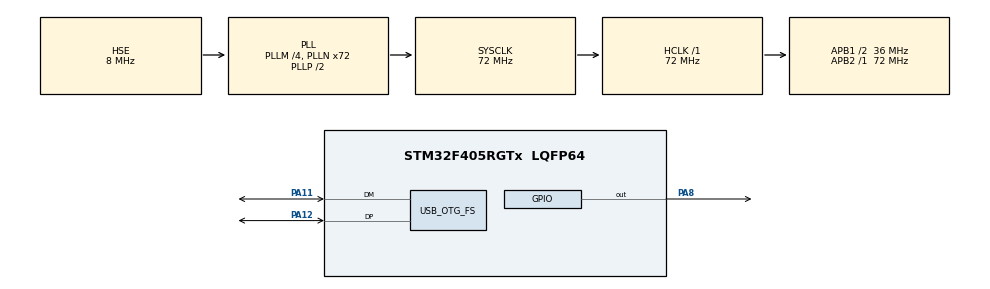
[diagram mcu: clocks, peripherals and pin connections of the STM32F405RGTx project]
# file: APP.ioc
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Mcu.Family=STM32F4
Mcu.Name=STM32F405RGTx
Mcu.Package=LQFP64
NVIC.OTG_FS_IRQn=true\:0\:0\:false\:false\:true\:false\:true\:true
NVIC.PriorityGroup=NVIC_PRIORITYGROUP_4
PA11.Mode=Device_Only
PA11.Signal=USB_OTG_FS_DM
PA12.Mode=Device_Only
PA12.Signal=USB_OTG_FS_DP
PA13.Mode=Serial_Wire
PA13.Signal=SYS_JTMS-SWDIO
PA14.Mode=Serial_Wire
PA14.Signal=SYS_JTCK-SWCLK
PA8.Signal=GPIO_Output
PH0-OSC_IN.Mode=HSE-External-Oscillator
PH0-OSC_IN.Signal=RCC_OSC_IN
PH1-OSC_OUT.Mode=HSE-External-Oscillator
PH1-OSC_OUT.Signal=RCC_OSC_OUT
ProjectManager.HeapSize=0x200
ProjectManager.StackSize=0x400
ProjectManager.TargetToolchain=MDK-ARM V5.32
RCC.48MHZClocksFreq_Value=48000000
RCC.AHBFreq_Value=72000000
RCC.APB1CLKDivider=RCC_HCLK_DIV2
RCC.APB1Freq_Value=36000000
RCC.APB1TimFreq_Value=72000000
RCC.APB2Freq_Value=72000000
RCC.APB2TimFreq_Value=72000000
RCC.CortexFreq_Value=72000000
RCC.HCLKFreq_Value=72000000
RCC.HSE_VALUE=8000000
RCC.HSI_VALUE=16000000
RCC.LSE_VALUE=32768
RCC.PLLM=4
RCC.PLLN=72
RCC.PLLQ=3
RCC.SYSCLKFreq_VALUE=72000000
RCC.SYSCLKSource=RCC_SYSCLKSOURCE_PLLCLK
RCC.VCOOutputFreq_Value=144000000
USB_DEVICE.CLASS_NAME_FS=CDC
USB_DEVICE.VirtualMode-CDC_FS=Cdc
USB_DEVICE.VirtualModeFS=Cdc_FS
USB_OTG_FS.VirtualMode=Device_Only
VP_USB_DEVICE_VS_USB_DEVICE_CDC_FS.Mode=CDC_FS
board=custom

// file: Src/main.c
/* USER CODE BEGIN Header */
/**
  ******************************************************************************
  * @file           : main.c
  * @brief          : Main program body
  ******************************************************************************
  * @attention
  *
  * Copyright (c) 2024 STMicroelectronics.
  * All rights reserved.
  *
  * This software is licensed under terms that can be found in the LICENSE file
  * in the root directory of this software component.
  * If no LICENSE file comes with this software, it is provided AS-IS.
  *
  ******************************************************************************
  */
/* USER CODE END Header */
#include "main.h"
#include "usb_device.h"
#include "gpio.h"

/* USER CODE BEGIN Includes */
#include "oled.h"
#include "usbd_cdc_if.h"
/* USER CODE END Includes */

/* USER CODE BEGIN PTD */

/* Flash 总大小和基地址 */
#define FLASH_BASE_ADDR       0x08000000    // Flash 起始地址
#define FLASH_TOTAL_SIZE      0x00100000    // 1MB 总大小

/* 每个部分的大小 */
#define FLASH_SIZE_APP0       0x00040000    // app0 大小：256KB (1MB / 4)
#define FLASH_SIZE_APP_BUF    0x00040000    // app_buf 大小：256KB
#define FLASH_SIZE_USER_VAR   0x00020000    // 用户变量大小：128KB (1MB / 8)
#define FLASH_SIZE_BOOTLOADER 0x00020000    // bootloader 大小：128KB
#define FLASH_SIZE_APP_INIT   0x00040000    // app_init 大小：256KB

/* 每个部分的起始地址 */
#define FLASH_ADDR_APP0       0x08000000    // app0 起始地址
#define FLASH_ADDR_APP_BUF    0x08040000    // app_buf 起始地址 (app0 起始地址 + 256KB)
#define FLASH_ADDR_USER_VAR   0x08080000    // 用户变量起始地址 (app_buf 起始地址 + 256KB)
#define FLASH_ADDR_BOOTLOADER 0x080A0000    // bootloader 起始地址 (用户变量起始地址 + 128KB)
#define FLASH_ADDR_APP_INIT   0x080C0000    // app_init 起始地址 (bootloader 起始地址 + 128KB)

#define ApplicationAddress     0x08004000
typedef  void (*pFunction)(void);
pFunction Jump_To_Application;
uint32_t JumpAddress;
extern USBD_HandleTypeDef hUsbDeviceFS;
/* USER CODE END PTD */

void SystemClock_Config(void);
/* USER CODE BEGIN PFP */

uint8_t jumpflag = 0;

void USB_DeInit(void)
{
  if (USBD_Stop(&hUsbDeviceFS) != USBD_OK)
  {
    Error_Handler();
  }
  if (USBD_DeInit(&hUsbDeviceFS) != USBD_OK)
  {
    Error_Handler();
  }
  HAL_Delay(100);
}

void USB_Init(void)
{
  GPIO_InitTypeDef GPIO_InitStruct = {0};

  /* GPIO Ports Clock Enable */
  __HAL_RCC_GPIOA_CLK_ENABLE();

  /*Configure GPIO pin Output Level */
  HAL_GPIO_WritePin(GPIOA, GPIO_PIN_11|GPIO_PIN_12, GPIO_PIN_RESET);

  /*Configure GPIO pin : PA8 */
  GPIO_InitStruct.Pin = GPIO_PIN_11|GPIO_PIN_12;
  GPIO_InitStruct.Mode = GPIO_MODE_OUTPUT_OD;
  GPIO_InitStruct.Pull = GPIO_PULLDOWN;
  GPIO_InitStruct.Speed = GPIO_SPEED_FREQ_LOW;
  HAL_GPIO_Init(GPIOA, &GPIO_InitStruct);

  HAL_GPIO_WritePin(GPIOA, GPIO_PIN_11 | GPIO_PIN_12, GPIO_PIN_RESET);
  HAL_Delay(50);
}

void ProcessReceivedData(uint8_t* data, uint32_t len)
{
  // 将接收到的数据转换为字符串
  data[256] = '\0'; // 确保字符串以 null 结尾

  // 检查接收到的消息是否为 "jump"
  if (strncmp((char*)data, "jump", len) == 0) {
      jumpflag = 1; // 设置跳转标志
  } else {
    // 在消息前面加上 "APP: "
    char message[256]; // 预留空间给前缀
    snprintf(message, sizeof(message), "APP: %s\r\n", data);

    // 通过 USB CDC 发送回去
    CDC_Transmit_FS((uint8_t *)message, strlen(message));
  }
}

void JumpTo(uint32_t address)
{
  if (((*(__IO uint32_t*)address) & 0x2FFE0000 ) == 0x20000000)
  {
    USB_DeInit();
    /* Jump to user application */
		SCB->VTOR = 0x000A0000;
    JumpAddress = *(__IO uint32_t*) (address + 4);
    Jump_To_Application = (pFunction) JumpAddress;
    /* Initialize user application's Stack Pointer */
    __set_MSP(*(__IO uint32_t*) address);
    Jump_To_Application();
  }
}
/* USER CODE END PFP */

int main(void)
{

  /* MCU Configuration--------------------------------------------------------*/

  /* Reset of all peripherals, Initializes the Flash interface and the Systick. */
  HAL_Init();

  /* Configure the system clock */
  SystemClock_Config();

  /* USER CODE BEGIN SysInit */
  USB_Init();
  /* USER CODE END SysInit */

  /* Initialize all configured peripherals */
  MX_GPIO_Init();
  MX_USB_DEVICE_Init();
  /* USER CODE BEGIN 2 */
  //OLED_Init();
  //OLED_Clear();
  /* USER CODE END 2 */

  /* Infinite loop */
  while (1)
  {
    /* USER CODE BEGIN 3 */
		HAL_GPIO_TogglePin(GPIOA, GPIO_PIN_8);
    HAL_Delay(100);
    if (jumpflag == 1)
    {
      JumpTo(FLASH_ADDR_BOOTLOADER);
    }
  }
  /* USER CODE END 3 */
}

void SystemClock_Config(void)
{
  RCC_OscInitTypeDef RCC_OscInitStruct = {0};
  RCC_ClkInitTypeDef RCC_ClkInitStruct = {0};

  /** Configure the main internal regulator output voltage
  */
  __HAL_RCC_PWR_CLK_ENABLE();
  __HAL_PWR_VOLTAGESCALING_CONFIG(PWR_REGULATOR_VOLTAGE_SCALE1);

  /** Initializes the RCC Oscillators according to the specified parameters
  * in the RCC_OscInitTypeDef structure.
  */
  RCC_OscInitStruct.OscillatorType = RCC_OSCILLATORTYPE_HSE;
  RCC_OscInitStruct.HSEState = RCC_HSE_ON;
  RCC_OscInitStruct.PLL.PLLState = RCC_PLL_ON;
  RCC_OscInitStruct.PLL.PLLSource = RCC_PLLSOURCE_HSE;
  RCC_OscInitStruct.PLL.PLLM = 4;
  RCC_OscInitStruct.PLL.PLLN = 72;
  RCC_OscInitStruct.PLL.PLLP = RCC_PLLP_DIV2;
  RCC_OscInitStruct.PLL.PLLQ = 3;
  if (HAL_RCC_OscConfig(&RCC_OscInitStruct) != HAL_OK)
  {
    Error_Handler();
  }

  /** Initializes the CPU, AHB and APB buses clocks
  */
  RCC_ClkInitStruct.ClockType = RCC_CLOCKTYPE_HCLK|RCC_CLOCKTYPE_SYSCLK
                              |RCC_CLOCKTYPE_PCLK1|RCC_CLOCKTYPE_PCLK2;
  RCC_ClkInitStruct.SYSCLKSource = RCC_SYSCLKSOURCE_PLLCLK;
  RCC_ClkInitStruct.AHBCLKDivider = RCC_SYSCLK_DIV1;
  RCC_ClkInitStruct.APB1CLKDivider = RCC_HCLK_DIV2;
  RCC_ClkInitStruct.APB2CLKDivider = RCC_HCLK_DIV1;

  if (HAL_RCC_ClockConfig(&RCC_ClkInitStruct, FLASH_LATENCY_2) != HAL_OK)
  {
    Error_Handler();
  }
}

void Error_Handler(void)
{
  __disable_irq();
  while (1)
  {
  }
}
